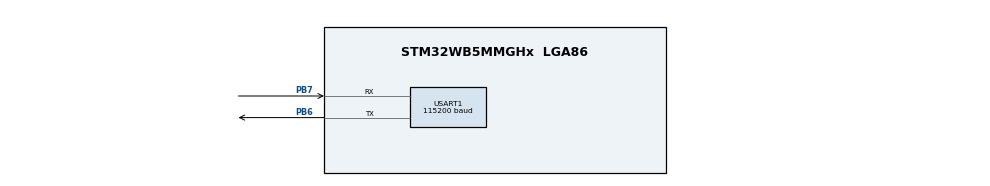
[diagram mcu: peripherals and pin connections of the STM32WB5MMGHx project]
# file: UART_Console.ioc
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Mcu.Family=STM32WB
Mcu.Name=STM32WB5MMGHx
Mcu.Package=LGA86
NVIC.PriorityGroup=NVIC_PRIORITYGROUP_4
PB6.GPIO_PuPd=GPIO_PULLUP
PB6.Mode=Asynchronous
PB6.Signal=USART1_TX
PB7.GPIO_PuPd=GPIO_PULLUP
PB7.Mode=Asynchronous
PB7.Signal=USART1_RX
ProjectManager.HeapSize=0x200
ProjectManager.StackSize=0x400
ProjectManager.TargetToolchain=EWARM V8
RCC.AHB2CLKDivider=RCC_SYSCLK_DIV2
RCC.AHBFreq_Value=64000000
RCC.APB1Freq_Value=64000000
RCC.APB1TimFreq_Value=64000000
RCC.APB2Freq_Value=64000000
RCC.APB2TimFreq_Value=64000000
RCC.APB3Freq_Value=16000000
RCC.CortexFreq_Value=64000000
RCC.HCLKFreq_Value=64000000
RCC.HSE_VALUE=32000000
RCC.HSI48_VALUE=48000000
RCC.HSI_VALUE=16000000
RCC.PLLN=32
RCC.SYSCLKFreq_VALUE=64000000
RCC.SYSCLKSource=RCC_SYSCLKSOURCE_PLLCLK
RCC.VCOOutputFreq_Value=128000000
USART1.AutoBaudRateEnableParam=UART_ADVFEATURE_AUTOBAUDRATE_DISABLE
USART1.BaudRate=115200
USART1.ClockPrescaler=PRESCALER_DIV1
USART1.DMADisableonRxErrorParam=ADVFEATURE_DMA_ENABLEONRXERROR
USART1.DataInvertParam=ADVFEATURE_DATAINV_DISABLE
USART1.FIFOMode=FIFOMODE_DISABLE
USART1.MSBFirstParam=ADVFEATURE_MSBFIRST_DISABLE
USART1.Mode=MODE_TX_RX
USART1.OneBitSampling=UART_ONE_BIT_SAMPLE_DISABLE
USART1.OverSampling=UART_OVERSAMPLING_16
USART1.OverrunDisableParam=ADVFEATURE_OVERRUN_ENABLE
USART1.Parity=PARITY_ODD
USART1.RXFIFOThreshold=RXFIFO_THRESHOLD_1EIGHTHFULL
USART1.RxPinLevelInvertParam=ADVFEATURE_RXINV_DISABLE
USART1.StopBits=STOPBITS_1
USART1.SwapParam=ADVFEATURE_SWAP_DISABLE
USART1.TXFIFOThreshold=TXFIFO_THRESHOLD_1EIGHTHFULL
USART1.TxPinLevelInvertParam=ADVFEATURE_TXINV_DISABLE
USART1.VirtualMode-Asynchronous=VM_ASYNC
USART1.WordLength=WORDLENGTH_8B
board=custom

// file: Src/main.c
/* USER CODE BEGIN Header */
/**
  ******************************************************************************
  * @file    main.c
  * @brief   This example shows how to retarget the C library printf/getchar functions
  *          to the UART.
  ******************************************************************************
  * @attention
  *
  * Copyright (c) 2020-2021 STMicroelectronics.
  * All rights reserved.
  *
  * This software is licensed under terms that can be found in the LICENSE file
  * in the root directory of this software component.
  * If no LICENSE file comes with this software, it is provided AS-IS.
  *
  ******************************************************************************
  */
/* USER CODE END Header */
#include "main.h"

/* USER CODE BEGIN Includes */
#if defined(__ICCARM__)
#include <LowLevelIOInterface.h>
#endif /* __ICCARM__ */
/* USER CODE END Includes */

UART_HandleTypeDef huart1;

/* USER CODE BEGIN PV */
aPwmLedGsData_TypeDef aPwmLedGsData;
/* USER CODE END PV */

void SystemClock_Config(void);
void PeriphCommonClock_Config(void);
static void MX_GPIO_Init(void);
static void MX_USART1_UART_Init(void);
/* USER CODE BEGIN PFP */
#if defined(__ICCARM__)
/* New definition from EWARM V9, compatible with EWARM8 */
int iar_fputc(int ch);
#define PUTCHAR_PROTOTYPE int iar_fputc(int ch)
#define GETCHAR_PROTOTYPE int fgetc(FILE *f)
#elif defined (__CC_ARM) || defined(__ARMCC_VERSION)
/* ARM Compiler 5/6 */
#define PUTCHAR_PROTOTYPE int fputc(int ch, FILE *f)
#define GETCHAR_PROTOTYPE int fgetc(FILE *f)
#elif defined(__GNUC__)
int __io_putchar(int ch);
#define PUTCHAR_PROTOTYPE int __io_putchar(int ch)
int __io_getchar(void);
#define GETCHAR_PROTOTYPE int __io_getchar(void)
#endif /* __ICCARM__ */
/* USER CODE END PFP */

int main(void)
{
  /* USER CODE BEGIN 1 */

  /* STM32WBxx HAL library initialization:
       - Configure the Flash prefetch
       - Systick timer is configured by default as source of time base, but user
         can eventually implement his proper time base source (a general purpose
         timer for example or other time source), keeping in mind that Time base
         duration should be kept 1ms since PPP_TIMEOUT_VALUEs are defined and
         handled in milliseconds basis.
       - Set NVIC Group Priority to 4
       - Low Level Initialization
     */
  /* USER CODE END 1 */

  /* MCU Configuration--------------------------------------------------------*/

  /* Reset of all peripherals, Initializes the Flash interface and the Systick. */
  HAL_Init();

  /* Configure the system clock */
  SystemClock_Config();

/* Configure the peripherals common clocks */
  PeriphCommonClock_Config();

  /* Initialize all configured peripherals */
  MX_GPIO_Init();
  MX_USART1_UART_Init();
  /* USER CODE BEGIN 2 */

  /* Configure the PWM LED */
  BSP_PWM_LED_Init();
  BSP_PWM_LED_Off();

  /* Output a message on Hyperterminal using printf function */
  printf("\n\r UART Printf Example: retarget the C library printf function to the UART\n\r");
  printf("** This message is printed using printf() function. ** \n\r");

  /* User is prompted to enter characters on terminal input.
     Entered characters are echoed on terminal output until a CR character is entered */
  printf("\n\r UART Getchar Example: retarget UART input to the C library getchar function\n\r");
  printf("Enter a string then press ENTER \n\r");
  fflush (stdout);

  uint8_t receivedchar;
  receivedchar= ' ';
  while(receivedchar!= '\n' && receivedchar != '\r')
  {
#if defined (__ICCARM__) || defined (__ARMCC_VERSION)
    receivedchar = fgetc(stdin);
#elif defined(__GNUC__)
    receivedchar = __io_getchar();
#endif /* __ICCARM__ || __ARMCC_VERSION */
  }

  /* End of example */
  printf("\n\rEnd of example\n\r");
  fflush (stdout);

  /* USER CODE END 2 */

  /* Infinite loop */
  /* USER CODE BEGIN WHILE */
  aPwmLedGsData[PWM_LED_RED]   = PWM_LED_GSDATA_OFF;
  aPwmLedGsData[PWM_LED_BLUE]  = PWM_LED_GSDATA_OFF;
  aPwmLedGsData[PWM_LED_GREEN] = PWM_LED_GSDATA_7_0;
  BSP_PWM_LED_On(aPwmLedGsData);

  while (1)
  {
    /* USER CODE END WHILE */

  }
}

void SystemClock_Config(void)
{
  RCC_OscInitTypeDef RCC_OscInitStruct = {0};
  RCC_ClkInitTypeDef RCC_ClkInitStruct = {0};

  /** Configure the main internal regulator output voltage
  */
  __HAL_PWR_VOLTAGESCALING_CONFIG(PWR_REGULATOR_VOLTAGE_SCALE1);

  /** Initializes the RCC Oscillators according to the specified parameters
  * in the RCC_OscInitTypeDef structure.
  */
  RCC_OscInitStruct.OscillatorType = RCC_OSCILLATORTYPE_HSI|RCC_OSCILLATORTYPE_MSI;
  RCC_OscInitStruct.HSIState = RCC_HSI_ON;
  RCC_OscInitStruct.MSIState = RCC_MSI_ON;
  RCC_OscInitStruct.HSICalibrationValue = RCC_HSICALIBRATION_DEFAULT;
  RCC_OscInitStruct.MSICalibrationValue = RCC_MSICALIBRATION_DEFAULT;
  RCC_OscInitStruct.MSIClockRange = RCC_MSIRANGE_6;
  RCC_OscInitStruct.PLL.PLLState = RCC_PLL_ON;
  RCC_OscInitStruct.PLL.PLLSource = RCC_PLLSOURCE_MSI;
  RCC_OscInitStruct.PLL.PLLM = RCC_PLLM_DIV1;
  RCC_OscInitStruct.PLL.PLLN = 32;
  RCC_OscInitStruct.PLL.PLLP = RCC_PLLP_DIV2;
  RCC_OscInitStruct.PLL.PLLR = RCC_PLLR_DIV2;
  RCC_OscInitStruct.PLL.PLLQ = RCC_PLLQ_DIV2;
  if (HAL_RCC_OscConfig(&RCC_OscInitStruct) != HAL_OK)
  {
    Error_Handler();
  }

  /** Configure the SYSCLKSource, HCLK, PCLK1 and PCLK2 clocks dividers
  */
  RCC_ClkInitStruct.ClockType = RCC_CLOCKTYPE_HCLK4|RCC_CLOCKTYPE_HCLK2
                              |RCC_CLOCKTYPE_HCLK|RCC_CLOCKTYPE_SYSCLK
                              |RCC_CLOCKTYPE_PCLK1|RCC_CLOCKTYPE_PCLK2;
  RCC_ClkInitStruct.SYSCLKSource = RCC_SYSCLKSOURCE_PLLCLK;
  RCC_ClkInitStruct.AHBCLKDivider = RCC_SYSCLK_DIV1;
  RCC_ClkInitStruct.APB1CLKDivider = RCC_HCLK_DIV1;
  RCC_ClkInitStruct.APB2CLKDivider = RCC_HCLK_DIV1;
  RCC_ClkInitStruct.AHBCLK2Divider = RCC_SYSCLK_DIV2;
  RCC_ClkInitStruct.AHBCLK4Divider = RCC_SYSCLK_DIV1;

  if (HAL_RCC_ClockConfig(&RCC_ClkInitStruct, FLASH_LATENCY_3) != HAL_OK)
  {
    Error_Handler();
  }
}

void PeriphCommonClock_Config(void)
{
  RCC_PeriphCLKInitTypeDef PeriphClkInitStruct = {0};

  /** Initializes the peripherals clock
  */
  PeriphClkInitStruct.PeriphClockSelection = RCC_PERIPHCLK_SMPS;
  PeriphClkInitStruct.SmpsClockSelection = RCC_SMPSCLKSOURCE_HSI;
  PeriphClkInitStruct.SmpsDivSelection = RCC_SMPSCLKDIV_RANGE1;

  if (HAL_RCCEx_PeriphCLKConfig(&PeriphClkInitStruct) != HAL_OK)
  {
    Error_Handler();
  }
}

static void MX_USART1_UART_Init(void)
{

  huart1.Instance = USART1;
  huart1.Init.BaudRate = 115200;
  huart1.Init.WordLength = UART_WORDLENGTH_8B;
  huart1.Init.StopBits = UART_STOPBITS_1;
  huart1.Init.Parity = UART_PARITY_ODD;
  huart1.Init.Mode = UART_MODE_TX_RX;
  huart1.Init.HwFlowCtl = UART_HWCONTROL_NONE;
  huart1.Init.OverSampling = UART_OVERSAMPLING_16;
  huart1.Init.OneBitSampling = UART_ONE_BIT_SAMPLE_DISABLE;
  huart1.Init.ClockPrescaler = UART_PRESCALER_DIV1;
  huart1.AdvancedInit.AdvFeatureInit = UART_ADVFEATURE_NO_INIT;
  if (HAL_UART_Init(&huart1) != HAL_OK)
  {
    Error_Handler();
  }
  if (HAL_UARTEx_SetTxFifoThreshold(&huart1, UART_TXFIFO_THRESHOLD_1_8) != HAL_OK)
  {
    Error_Handler();
  }
  if (HAL_UARTEx_SetRxFifoThreshold(&huart1, UART_RXFIFO_THRESHOLD_1_8) != HAL_OK)
  {
    Error_Handler();
  }
  if (HAL_UARTEx_DisableFifoMode(&huart1) != HAL_OK)
  {
    Error_Handler();
  }

}

static void MX_GPIO_Init(void)
{

  /* GPIO Ports Clock Enable */
  __HAL_RCC_GPIOB_CLK_ENABLE();

}

/* USER CODE BEGIN 4 */
#if defined(__ICCARM__)
/**
  * @brief  Retargets the C library __write function to the IAR function iar_fputc.
  * @param  file: file descriptor.
  * @param  ptr: pointer to the buffer where the data is stored.
  * @param  len: length of the data to write in bytes.
  * @retval length of the written data in bytes.
  */
size_t __write(int file, unsigned char const *ptr, size_t len)
{
  size_t idx;
  unsigned char const *pdata = ptr;

  for (idx = 0; idx < len; idx++)
  {
    iar_fputc((int)*pdata);
    pdata++;
  }
  return len;
}
#endif /* __ICCARM__ */

/**
  * @brief  Retargets the C library printf function to the USART.
  * @param  None
  * @retval None
  */
PUTCHAR_PROTOTYPE
{
  /* Place your implementation of fputc here */
  /* e.g. write a character to the USART1 and Loop until the end of transmission */
  HAL_UART_Transmit(&huart1, (uint8_t *)&ch, 1, 0xFFFF);

  return ch;
}

GETCHAR_PROTOTYPE
{
  uint8_t ch = 0;
  /* Place your implementation of fgetc here */

  /* Clear the Overrun flag just before receiving the first character */
  __HAL_UART_CLEAR_OREFLAG(&huart1);

  /* Wait for reception of a character on the USART1 RX line
     and echo this character on console */
  HAL_UART_Receive(&huart1, (uint8_t *)&ch, 1, 0xFFFF);
  HAL_UART_Transmit(&huart1, (uint8_t *)&ch, 1, 0xFFFF);
  return ch;
}

/* USER CODE END 4 */

void Error_Handler(void)
{
  /* USER CODE BEGIN Error_Handler_Debug */
  /* User can add his own implementation to report the HAL error return state */
  aPwmLedGsData[PWM_LED_RED]   = PWM_LED_GSDATA_7_0;
  aPwmLedGsData[PWM_LED_GREEN] = PWM_LED_GSDATA_OFF;
  aPwmLedGsData[PWM_LED_BLUE]  = PWM_LED_GSDATA_OFF;
  BSP_PWM_LED_On(aPwmLedGsData);

  __disable_irq();
  while (1)
  {
  }
  /* USER CODE END Error_Handler_Debug */
}
